# STM32WBA62 register map
File version: 1.1
CPU: CM33 r0p1, little endian, MPU, FPU, 4 interrupt priority bits
Registers are 32-bit, read-write, reset 0x0 unless marked. A register's access mark holds for its fields unless they carry their own. Offsets are from the block's base; [hi:lo] are bit positions; {n}, {i} and the like mark numbered series.

## GPIOG — GPIOG address block description
Base 0x42021800
Same registers: SEC_GPIOG 0x52021800
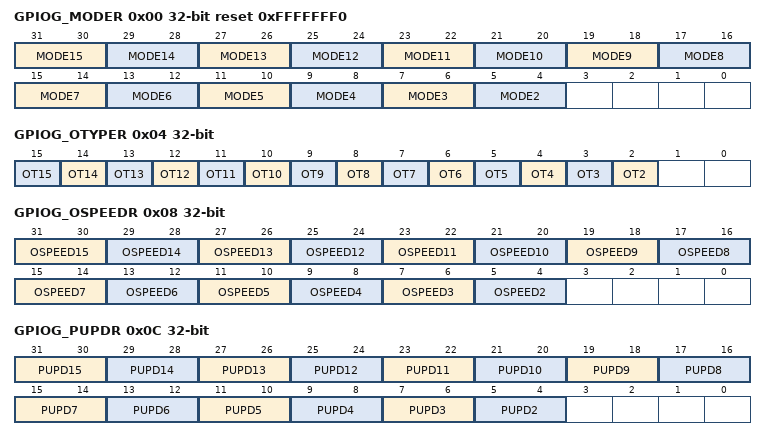
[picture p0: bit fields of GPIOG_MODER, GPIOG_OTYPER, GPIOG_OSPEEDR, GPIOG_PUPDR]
0x00 GPIOG_MODER reset 0xFFFFFFF0 — GPIO port G mode register
  [31:30] MODE15 — Port G configuration I/O pin 15
    0=Input mode; 1=General purpose output mode; 2=Alternate function mode; 3=Analog mode (reset state)
  [2n+1:2n] MODE{n} (n=2..14) — Port configuration I/O pin {n}
0x04 GPIOG_OTYPER — GPIO port G output type register
  [all] fields
    0=Output push-pull (reset state); 1=Output open-drain
  [n] OT{n} (n=2..15) — Port configuration I/O pin y
0x08 GPIOG_OSPEEDR — GPIO port G output speed register
  [31:30] OSPEED15 — Port configuration I/O pin 15
    0=Low speed; 1=Medium speed; 2=High speed
  [2n+1:2n] OSPEED{n} (n=2..14) — Port configuration I/O pin {n}
0x0C GPIOG_PUPDR — GPIO port G pull-up/pull-down register
  [31:30] PUPD15 — Port configuration I/O pin 15
    0=No pull-up, pull-down; 1=Pull-up; 2=Pull-down
  [2n+1:2n] PUPD{n} (n=2..14) — Port configuration I/O pin {n}
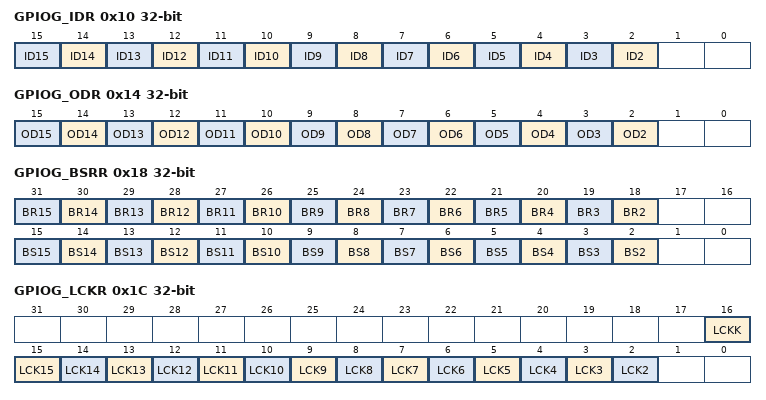
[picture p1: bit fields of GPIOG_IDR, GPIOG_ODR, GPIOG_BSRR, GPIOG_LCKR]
0x10 GPIOG_IDR ro (reset mask 0xFFFF0FFF) — GPIO port G input data register
  [n] ID{n} (n=2..15) — Port input data I/O pin y
0x14 GPIOG_ODR — GPIO port G output data register
  [n] OD{n} (n=2..15) — Port output data I/O pin y
0x18 GPIOG_BSRR wo — GPIO port G bit set/reset register
  [n+16] BR{n} (n=2..15) — Port reset I/O pin y
    0=No action on the corresponding ODy bit; 1=Resets the corresponding ODy bit
  [n] BS{n} (n=2..15) — Port set I/O pin y
    0=No action on the corresponding ODy bit; 1=Sets the corresponding ODy bit
0x1C GPIOG_LCKR — GPIO port G configuration lock register
  [16] LCKK — Lock key
    0=Port configuration lock key not active; 1=Port configuration lock key active
  [n] LCK{n} (n=2..15) — Port lock I/O pin y
    0=Port configuration not locked; 1=Port configuration locked
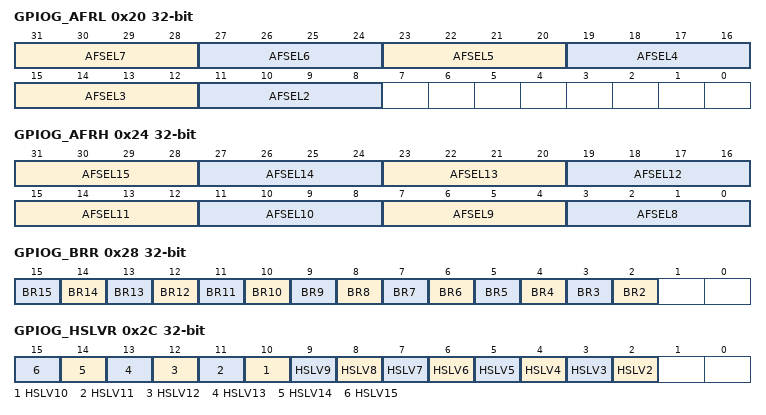
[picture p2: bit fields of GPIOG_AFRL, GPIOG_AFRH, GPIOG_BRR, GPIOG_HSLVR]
0x20 GPIOG_AFRL — GPIO port G alternate function low register
  [31:28] AFSEL7 — Alternate function selection for port I/O pin 7
    {v}=AF{v} (v=0..15)
  [4n+3:4n] AFSEL{n} (n=2..6) — Alternate function selection for port I/O pin {n}
0x24 GPIOG_AFRH — GPIO port G alternate function high register
  [31:28] AFSEL15 — Alternate function selection for port I/O pin 15
    {v}=AF{v} (v=0..15)
  [4n-29:4n-32] AFSEL{n} (n=8..14) — Alternate function selection for port I/O pin {n}
0x28 GPIOG_BRR wo — GPIO port G bit reset register
  [all] fields
    0=No action on the corresponding ODy bit; 1=Reset the corresponding ODy bit
  [n] BR{n} (n=2..15) — Port reset I/O pin y
0x2C GPIOG_HSLVR — GPIO port G high-speed low-voltage register
  [all] fields
    0=I/O speed optimization disabled; 1=I/O speed optimization enabled
  [n] HSLV{n} (n=2..15) — Port G high-speed low-voltage configuration
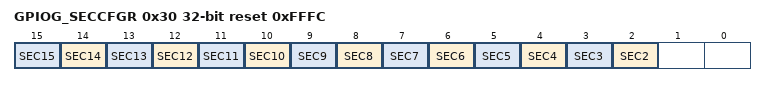
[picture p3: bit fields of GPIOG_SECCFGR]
0x30 GPIOG_SECCFGR reset 0xFFFC — GPIO port G secure configuration register
  [all] fields
    0=The I/O pin is non-secure; 1=The I/O pin is secure
  [n] SEC{n} (n=2..15) — I/O pin of port secure bit enable y

## GPIOH — GPIOH address block description
Base 0x42021C00
Same registers: SEC_GPIOH 0x52021C00
0x00 GPIOH_MODER reset 0xC0 — GPIO port H mode register
  [7:6] MODE3 — Port H configuration I/O pin 3
    0=Input mode; 1=General purpose output mode; 2=Alternate function mode; 3=Analog mode (reset state)
0x04 GPIOH_OTYPER — GPIO port H output type register
  [3] OT3 — Port H configuration I/O pin 3
    0=Output push-pull (reset state); 1=Output open-drain
0x08 GPIOH_OSPEEDR — GPIO port H output speed register
  [7:6] OSPEED3 — Port H configuration I/O pin 3
    0=Low speed; 1=Medium speed; 2=High speed
0x0C GPIOH_PUPDR — GPIO port H pull-up/pull-down register
  [7:6] PUPD3 — Port H configuration I/O pin 3
    0=No pull-up, pull-down; 1=Pull-up; 2=Pull-down
0x10 GPIOH_IDR ro (reset mask 0xFFFF0000) — GPIO port H input data register
  [3] ID3 — Port H input data I/O pin 3
0x14 GPIOH_ODR — GPIO port H output data register
  [3] OD3 — Port H output data I/O pin 3
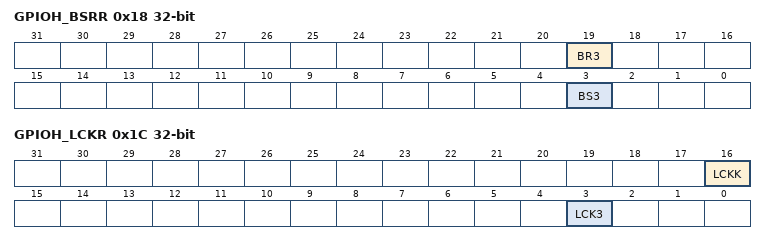
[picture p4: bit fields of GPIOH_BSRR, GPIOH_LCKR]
0x18 GPIOH_BSRR wo — GPIO port H bit set/reset register
  [19] BR3 — Port H reset I/O pin 3
    0=No action on the corresponding OD3 bit; 1=Resets the corresponding OD3 bit
  [3] BS3 — Port H set I/O pin 3
    0=No action on the corresponding OD3 bit; 1=Sets the corresponding OD3 bit
0x1C GPIOH_LCKR — GPIO port H configuration lock register
  [16] LCKK — Lock key
    0=Port configuration lock key not active; 1=Port configuration lock key active
  [3] LCK3 — Port H lock I/O pin 3
    0=Port configuration not locked; 1=Port configuration locked
0x20 GPIOH_AFRL — GPIO port H alternate function low register
  [15:12] AFSEL3 — Alternate function selection for port H I/O pin 3
    {v}=AF{v} (v=0..15)
0x28 GPIOH_BRR wo — GPIO port H bit reset register
  [3] BR3 — Port H reset I/O pin 3
    0=No action on the corresponding OD3 bit; 1=Reset the corresponding OD3 bit
0x30 GPIOH_SECCFGR reset 0x8 — GPIO port H secure configuration register
  [3] SEC3 — I/O pin of port H secure bit enable 3
    0=The I/O pin is nonsecure; 1=The I/O pin is secure
